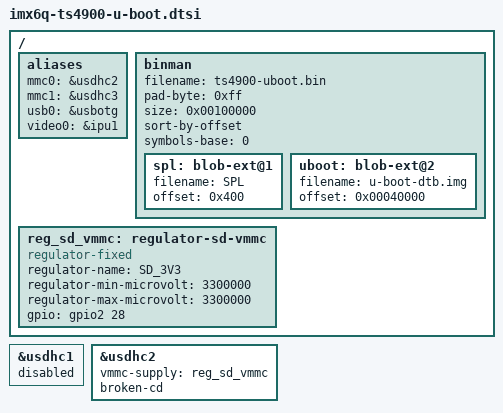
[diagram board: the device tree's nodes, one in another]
/ {
        aliases {
                mmc0 = &usdhc2;
                mmc1 = &usdhc3;
                usb0 = &usbotg;
                video0 = &ipu1;
        };

	binman {
		filename = "ts4900-uboot.bin";
		pad-byte = <0xff>;
		size = <0x00100000>;
		sort-by-offset;
		symbols-base = <0>;

		spl: blob-ext@1 {
			filename = "SPL";
			/* XXX: TODO: Verify this offset is needed */
			offset = <0x400>;
		};

		uboot: blob-ext@2 {
			filename = "u-boot-dtb.img";
			// Must match CONFIG_SYS_SPI_U_BOOT_OFFS!
			offset = <0x00040000>; // XXX: TODO: Better align this
		};

/*
		fpga_bitstream: blob-ext@3 {
			filename = "ts4900-fpga.bin";
			align = <0x1000>;
		};
*/
	};
		

	reg_sd_vmmc: regulator-sd-vmmc {
		compatible = "regulator-fixed";
		regulator-name = "SD_3V3";
		regulator-min-microvolt = <3300000>;
		regulator-max-microvolt = <3300000>;
		gpio = <&gpio2 28 GPIO_ACTIVE_HIGH>;
	};
};

&usdhc1 {
	status = "disabled";
};

&usdhc2 {
	vmmc-supply = <&reg_sd_vmmc>;
	broken-cd;
};
